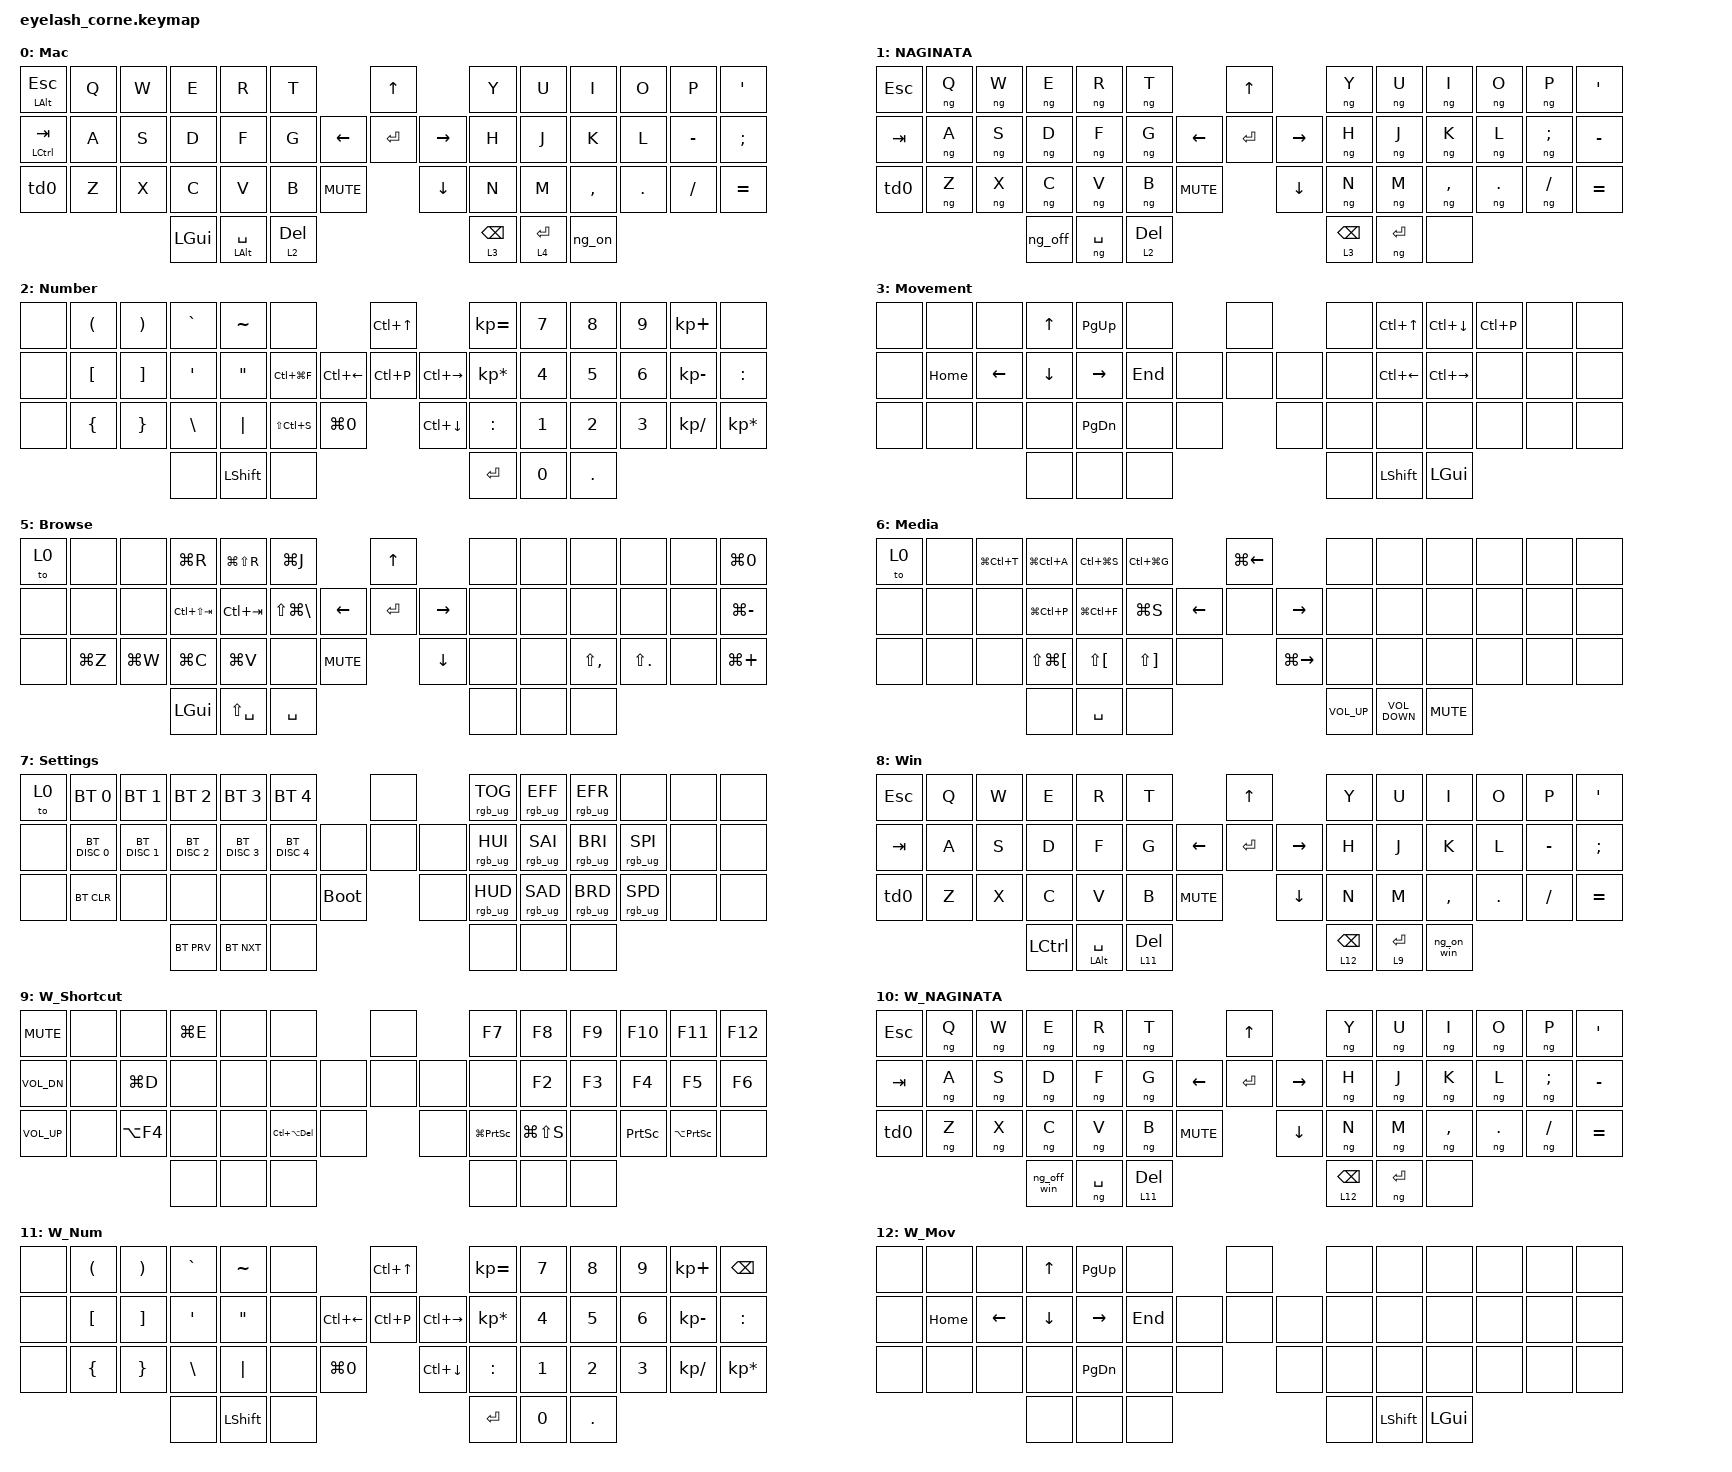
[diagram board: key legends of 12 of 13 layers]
#include <dt-bindings/zmk/mouse.h>
#include <input/processors.dtsi>
#include <behaviors/naginata.dtsi>
#include <behaviors.dtsi>
#include <dt-bindings/zmk/bt.h>
#include <dt-bindings/zmk/keys.h>
#include <dt-bindings/zmk/pointing.h>
#include <dt-bindings/zmk/rgb.h>

/*

   &mmv_input_listener {
       input-processors = <&zip_xy_scaler 2 1>;
   };

   &msc_input_listener {
       input-processors = <&zip_xy_scaler 2 1>;
   };

 */

#define ZMK_MOUSE_DEFAULT_MOVE_VAL 1200  // 600
#define ZMK_MOUSE_DEFAULT_SCRL_VAL 20    // 10

/ {
    behaviors {
        td0: td0 {
            compatible = "zmk,behavior-tap-dance";
            display-name = "Shift/Caps Lock Tap Dance";
            #binding-cells = <0>;
            bindings = <&kp LEFT_SHIFT>, <&kp CAPS>;

            label = "Shift";
        };

        mt_impl: mod-tap-by-hold-tap {
            compatible = "zmk,behavior-hold-tap";
            label = "MOD_TAP_BY_HOLD_TAP";
            #binding-cells = <2>;
            tapping-term-ms = <200>;
            quick-tap-ms = <0>;
            flavor = "hold-preferred";
            bindings = <&kp>, <&kp>;
        };

        lt_impl: layer-tap-by-hold-tap {
            compatible = "zmk,behavior-hold-tap";
            label = "LAYER_TAP_BY_HOLD_TAP";
            #binding-cells = <2>;
            tapping-term-ms = <200>;
            quick-tap-ms = <0>;
            flavor = "tap-preferred";
            bindings = <&mo>, <&kp>;
        };
    };

    rgb_encoder: rgb_encoder {
        compatible = "zmk,behavior-sensor-rotate";
        #sensor-binding-cells = <0>;
        bindings = <&rgb_ug RGB_BRI>, <&rgb_ug RGB_BRD>;
    };

    scroll_encoder: scroll_encoder {
        compatible = "zmk,behavior-sensor-rotate";
        #sensor-binding-cells = <0>;
        bindings = <&msc SCRL_DOWN>, <&msc SCRL_UP>;

        tap-ms = <30>;
    };

    macros {
        ng_on: ng_on {
            compatible = "zmk,behavior-macro";
            #binding-cells = <0>;
            bindings = <&macro_tap>, <&kp LANGUAGE_1 &kp INTERNATIONAL_4 &to 1>;
        };

        ng_off: ng_off {
            compatible = "zmk,behavior-macro";
            #binding-cells = <0>;
            bindings = <&macro_tap>, <&kp LANGUAGE_2 &kp INTERNATIONAL_5 &to 0>;
        };

        kakko: kakko {
            compatible = "zmk,behavior-macro";
            #binding-cells = <0>;
            bindings = <&macro_tap>, <&kp LEFT_PARENTHESIS &kp RPAR &kp LC(B)>;

            label = "KAKKO";
        };

        ng_kakko1: ng_kakko1 {
            compatible = "zmk,behavior-macro";
            #binding-cells = <0>;
            bindings =
                <&macro_tap>,
                <&kp LEFT_PARENTHESIS &kp RPAR &kp ENTER &kp LC(B)>;

            label = "NG_KAKKO1";
        };

        ng_kakko2: ng_kakko2 {
            compatible = "zmk,behavior-macro";
            #binding-cells = <0>;
            bindings = <&macro_tap>, <&kp LPAR &kp RPAR>;

            label = "NG_KAKKO2";
            wait-ms = <300>;
            tap-ms = <150>;
        };

        win_mode: win_mode {
            compatible = "zmk,behavior-macro";
            #binding-cells = <0>;
            bindings =
                <&macro_press>,
                <&to 8 &bt BT_SEL 1 &rgb_ug RGB_ON &rgb_ug RGB_COLOR_HSB(230,100,48) &rgb_ug RGB_EFF>;

            label = "WIN_MODE";
        };

        mac_mode: mac_mode {
            compatible = "zmk,behavior-macro";
            #binding-cells = <0>;
            bindings =
                <&macro_press>,
                <&to 0 &bt BT_SEL 0 &rgb_ug RGB_ON &rgb_ug RGB_COLOR_HSB(0,100,50) &rgb_ug RGB_EFR>;

            label = "MAC_MODE";
        };

        ng_off_win: ng_off_win {
            compatible = "zmk,behavior-macro";
            #binding-cells = <0>;
            bindings = <&macro_tap>, <&kp LANGUAGE_2 &kp INTERNATIONAL_5 &to 8>;

            label = "NG_OFF_WIN";
        };

        ng_on_win: ng_on_win {
            compatible = "zmk,behavior-macro";
            #binding-cells = <0>;
            bindings =
                <&macro_tap>,
                <&kp LANGUAGE_1 &kp INTERNATIONAL_4 &to 10>;

            label = "NG_ON_WIN";
        };
    };

    combos {
        compatible = "zmk,combos";

        Browse {
            bindings = <&to 5>;
            key-positions = <29 14>;
            layers = <0>;
        };

        Media {
            bindings = <&to 6>;
            key-positions = <15 30>;
            layers = <0>;
        };

        combo_ng_on {
            timeout-ms = <300>;
            key-positions = <22 23>;
            bindings = <&ng_on>;
            layers = <0>;
        };

        combo_ng_off {
            timeout-ms = <300>;
            key-positions = <17 18>;
            bindings = <&ng_off>;
            layers = <0 1>;
        };

        System {
            bindings = <&to 7>;
            key-positions = <40 26 11>;
            layers = <0>;
            timeout-ms = <300>;
        };

        ng_nakaguro {
            bindings = <&kp SLASH>;
            key-positions = <23 24 5>;
            layers = <1 10>;
            timeout-ms = <300>;
            require-prior-idle-ms = <0>;
        };

        ng_Kata {
            bindings = <&kp LC(K)>;
            key-positions = <24 38>;
            layers = <1>;
            timeout-ms = <300>;
        };

        Emo {
            bindings = <&kp LG(LC(SPACE))>;
            key-positions = <26 40>;
            layers = <1 0>;
            timeout-ms = <300>;
        };

        ng_Hira {
            bindings = <&kp LC(J)>;
            key-positions = <23 37>;
            timeout-ms = <300>;
            layers = <1>;
        };

        kakko {
            bindings = <&kakko>;
            key-positions = <23 24 17>;
            layers = <0 8>;
            timeout-ms = <300>;
        };

        ng_kakko1 {
            bindings = <&ng_kakko1>;
            key-positions = <17 23 24>;
            layers = <1 10>;
            timeout-ms = <300>;
        };

        ng_kakko2 {
            bindings = <&ng_kakko2>;
            key-positions = <24 15 25>;
            layers = <1 10>;
            timeout-ms = <300>;
            slow-release;
        };

        windowskey {
            bindings = <&kp LEFT_WIN>;
            key-positions = <42 43>;
            timeout-ms = <300>;
            layers = <8>;
        };

        win_mode {
            bindings = <&win_mode>;
            key-positions = <7 22 36>;
            layers = <0>;
            timeout-ms = <300>;
        };

        Mac_mode {
            bindings = <&mac_mode>;
            key-positions = <7 22 36>;
            layers = <8>;
            timeout-ms = <300>;
        };
    };

    keymap {
        compatible = "zmk,keymap";

        Mac {
            display-name = "Mac";
            bindings = <
&mt_impl LALT ESCAPE       &kp Q  &kp W  &kp E     &kp R                &kp T                                   &kp UP                &kp Y                 &kp U             &kp I      &kp O    &kp P      &kp SINGLE_QUOTE
&mt_impl LEFT_CONTROL TAB  &kp A  &kp S  &kp D     &kp F                &kp G                         &kp LEFT  &kp ENTER  &kp RIGHT  &kp H                 &kp J             &kp K      &kp L    &kp MINUS  &kp SEMI
&td0                       &kp Z  &kp X  &kp C     &kp V                &kp B           &kp K_MUTE              &kp DOWN              &kp N                 &kp M             &kp COMMA  &kp DOT  &kp FSLH   &kp EQUAL
                                         &kp LGUI  &mt_impl LALT SPACE  &lt_impl 2 DEL                                                &lt_impl 3 BACKSPACE  &lt_impl 4 ENTER  &ng_on
            >;

            sensor-bindings = <&inc_dec_kp C_VOLUME_UP C_VOLUME_DOWN>;
            label = "Mac";
        };

        naginata_layer {
            bindings = <
&kp ESCAPE  &ng Q  &ng W  &ng E    &ng R      &ng T                                   &kp UP                &ng Y                 &ng U      &ng I      &ng O    &ng P     &kp SINGLE_QUOTE
&kp TAB     &ng A  &ng S  &ng D    &ng F      &ng G                         &kp LEFT  &kp ENTER  &kp RIGHT  &ng H                 &ng J      &ng K      &ng L    &ng SEMI  &kp MINUS
&td0        &ng Z  &ng X  &ng C    &ng V      &ng B           &kp K_MUTE              &kp DOWN              &ng N                 &ng M      &ng COMMA  &ng DOT  &ng FSLH  &kp EQUAL
                          &ng_off  &ng SPACE  &lt_impl 2 DEL                                                &lt_impl 3 BACKSPACE  &ng ENTER  &none
            >;

            sensor-bindings = <&inc_dec_kp C_VOLUME_UP C_VOLUME_DOWN>;
            label = "NAGINATA";
        };

        Layer_2 {
            bindings = <
&none  &kp LPAR  &kp RPAR           &kp GRAVE         &kp TILDE          &none                                      &kp LC(UP_ARROW)                   &kp KP_EQUAL     &kp N7  &kp N8   &kp N9  &kp KP_PLUS      &none
&none  &kp LBKT  &kp RIGHT_BRACKET  &kp SINGLE_QUOTE  &kp DOUBLE_QUOTES  &kp LC(LG(F))                &kp LC(LEFT)  &kp LC(P)           &kp LC(RIGHT)  &kp KP_MULTIPLY  &kp N4  &kp N5   &kp N6  &kp KP_SUBTRACT  &kp COLON
&none  &kp LBRC  &kp RIGHT_BRACE    &kp BACKSLASH     &kp PIPE           &kp LS(LC(S))  &kp LG(N0)                  &kp LC(DOWN_ARROW)                 &kp COLON        &kp N1  &kp N2   &kp N3  &kp KP_DIVIDE    &kp KP_ASTERISK
                                    &none             &kp LSHFT          &none                                                                         &kp ENTER        &kp N0  &kp DOT
            >;

            label = "Number";
            sensor-bindings = <&inc_dec_kp LG(PLUS) LG(MINUS)>;
        };

        Layer_3 {
            bindings = <
&none  &none     &none     &kp UP_ARROW    &kp PAGE_UP    &none                    &none         &none  &kp LC(UP_ARROW)  &kp LC(DOWN_ARROW)  &kp LC(P)  &none  &none
&none  &kp HOME  &kp LEFT  &kp DOWN_ARROW  &kp RIGHT      &kp END           &none  &none  &none  &none  &kp LC(LEFT)      &kp LC(RIGHT)       &none      &none  &none
&none  &none     &none     &none           &kp PAGE_DOWN  &none    &none           &none         &none  &none             &none               &none      &none  &none
                           &none           &none          &none                                  &none  &kp LEFT_SHIFT    &kp LGUI
            >;

            sensor-bindings = <&scroll_encoder>;
            label = "Movement";
        };

        Layer_4 {
            bindings = <
&kp K_MUTE    &none  &none  &none  &none  &none                  &none         &kp F7                &kp F8                &kp F9          &kp F10                   &kp F11                   &kp F12
&kp C_VOL_DN  &none  &none  &none  &none  &none           &none  &none  &none  &kp F1                &kp F2                &kp F3          &kp F4                    &kp F5                    &kp F6
&kp C_VOL_UP  &none  &none  &none  &none  &none  &none           &none         &kp LG(LS(NUMBER_3))  &kp LS(LG(NUMBER_4))  &kp LS(LG(N5))  &kp LS(LC(LG(NUMBER_3)))  &kp LS(LC(LG(NUMBER_4)))  &none
                            &none  &none  &none                                &none                 &none                 &none
            >;

            sensor-bindings = <&scroll_encoder>;
            label = "Shortcuts";
        };

        layer_5 {
            bindings = <
&to 0  &none      &none      &kp LG(R)        &kp LG(LS(R))  &kp LG(J)                                      &kp UP_ARROW               &none  &none  &none          &none           &none  &kp LG(NUMBER_0)
&none  &none      &none      &kp LC(LS(TAB))  &kp LC(TAB)    &kp LS(LG(BACKSLASH))                &kp LEFT  &kp ENTER       &kp RIGHT  &none  &none  &none          &none           &none  &kp LG(MINUS)
&none  &kp LG(Z)  &kp LG(W)  &kp LG(C)        &kp LG(V)      &none                  &kp K_MUTE              &kp DOWN_ARROW             &none  &none  &kp LS(COMMA)  &kp LS(PERIOD)  &none  &kp LG(PLUS)
                             &kp LGUI         &kp LS(SPACE)  &kp SPACE                                                                 &none  &none  &none
            >;

            label = "Browse";
            sensor-bindings = <&inc_dec_kp C_VOLUME_UP C_VOLUME_DOWN>;
        };

        layer_6 {
            bindings = <
&to 0  &none  &kp LG(LC(T))  &kp LG(LC(A))             &kp LC(LG(S))         &kp LC(LG(G))                             &kp LG(LEFT)              &none            &none              &none       &none  &none  &none
&none  &none  &none          &kp LG(LC(P))             &kp LG(LC(F))         &kp LG(S)                       &kp LEFT  &none          &kp RIGHT  &none            &none              &none       &none  &none  &none
&none  &none  &none          &kp LS(LG(LEFT_BRACKET))  &kp LS(LEFT_BRACKET)  &kp LS(RIGHT_BRACKET)  &none              &kp LG(RIGHT)             &none            &none              &none       &none  &none  &none
                             &none                     &kp SPACE             &none                                                               &kp C_VOLUME_UP  &kp C_VOLUME_DOWN  &kp K_MUTE
            >;

            label = "Media";
            sensor-bindings = <&inc_dec_kp RIGHT LEFT>;
        };

        System {
            bindings = <
&to 0  &bt BT_SEL 0   &bt BT_SEL 1   &bt BT_SEL 2   &bt BT_SEL 3   &bt BT_SEL 4                         &none         &rgb_ug RGB_TOG  &rgb_ug RGB_EFF  &rgb_ug RGB_EFR  &none            &none  &none
&none  &bt BT_DISC 0  &bt BT_DISC 1  &bt BT_DISC 2  &bt BT_DISC 3  &bt BT_DISC 4                 &none  &none  &none  &rgb_ug RGB_HUI  &rgb_ug RGB_SAI  &rgb_ug RGB_BRI  &rgb_ug RGB_SPI  &none  &none
&none  &bt BT_CLR     &none          &none          &none          &none          &bootloader           &none         &rgb_ug RGB_HUD  &rgb_ug RGB_SAD  &rgb_ug RGB_BRD  &rgb_ug RGB_SPD  &none  &none
                                     &bt BT_PRV     &bt BT_NXT     &none                                              &none            &none            &none
            >;

            sensor-bindings = <&rgb_encoder>;
            label = "Settings";
        };

        Windows {
            display-name = "Win";
            bindings = <
&kp ESCAPE  &kp Q  &kp W  &kp E             &kp R           &kp T                                    &kp UP                &kp Y                  &kp U             &kp I       &kp O    &kp P      &kp SINGLE_QUOTE
&kp TAB     &kp A  &kp S  &kp D             &kp F           &kp G                          &kp LEFT  &kp ENTER  &kp RIGHT  &kp H                  &kp J             &kp K       &kp L    &kp MINUS  &kp SEMI
&td0        &kp Z  &kp X  &kp C             &kp V           &kp B            &kp K_MUTE              &kp DOWN              &kp N                  &kp M             &kp COMMA   &kp DOT  &kp FSLH   &kp EQUAL
                          &kp LEFT_CONTROL  &mt LALT SPACE  &lt_impl 11 DEL                                                &lt_impl 12 BACKSPACE  &lt_impl 9 ENTER  &ng_on_win
            >;

            sensor-bindings = <&inc_dec_kp C_VOLUME_UP C_VOLUME_DOWN>;
            label = "Win";
        };

        Win2 {
            label = "W_Shortcut";
            bindings = <
&kp K_MUTE    &none  &none       &kp LG(E)  &none  &none                            &none         &kp F7               &kp F8         &kp F9  &kp F10          &kp F11              &kp F12
&kp C_VOL_DN  &none  &kp LG(D)   &none      &none  &none                     &none  &none  &none  &none                &kp F2         &kp F3  &kp F4           &kp F5               &kp F6
&kp C_VOL_UP  &none  &kp LA(F4)  &none      &none  &kp LC(LA(DEL))  &none           &none         &kp LG(PRINTSCREEN)  &kp LG(LS(S))  &none   &kp PRINTSCREEN  &kp LA(PRINTSCREEN)  &none
                                 &none      &none  &none                                          &none                &none          &none
            >;

            sensor-bindings = <&scroll_encoder>;
        };

        layer_10 {
            label = "W_NAGINATA";
            bindings = <
&kp ESCAPE  &ng Q  &ng W  &ng E        &ng R      &ng T                                    &kp UP                &ng Y                  &ng U      &ng I      &ng O    &ng P     &kp SINGLE_QUOTE
&kp TAB     &ng A  &ng S  &ng D        &ng F      &ng G                          &kp LEFT  &kp ENTER  &kp RIGHT  &ng H                  &ng J      &ng K      &ng L    &ng SEMI  &kp MINUS
&td0        &ng Z  &ng X  &ng C        &ng V      &ng B            &kp K_MUTE              &kp DOWN              &ng N                  &ng M      &ng COMMA  &ng DOT  &ng FSLH  &kp EQUAL
                          &ng_off_win  &ng SPACE  &lt_impl 11 DEL                                                &lt_impl 12 BACKSPACE  &ng ENTER  &none
            >;

            sensor-bindings = <&inc_dec_kp C_VOLUME_UP C_VOLUME_DOWN>;
        };

        layer_11 {
            label = "W_Num";
            bindings = <
&none  &kp LPAR  &kp RPAR           &kp GRAVE         &kp TILDE          &none                              &kp LC(UP_ARROW)                   &kp KP_EQUAL     &kp N7  &kp N8   &kp N9  &kp KP_PLUS      &kp BACKSPACE
&none  &kp LBKT  &kp RIGHT_BRACKET  &kp SINGLE_QUOTE  &kp DOUBLE_QUOTES  &none                &kp LC(LEFT)  &kp LC(P)           &kp LC(RIGHT)  &kp KP_MULTIPLY  &kp N4  &kp N5   &kp N6  &kp KP_SUBTRACT  &kp COLON
&none  &kp LBRC  &kp RIGHT_BRACE    &kp BACKSLASH     &kp PIPE           &none  &kp LG(N0)                  &kp LC(DOWN_ARROW)                 &kp COLON        &kp N1  &kp N2   &kp N3  &kp KP_DIVIDE    &kp KP_ASTERISK
                                    &none             &kp LSHFT          &none                                                                 &kp ENTER        &kp N0  &kp DOT
            >;

            sensor-bindings = <&inc_dec_kp LG(PLUS) LG(MINUS)>;
        };

        layer_12 {
            label = "W_Mov";
            bindings = <
&none  &none     &none     &kp UP_ARROW    &kp PAGE_UP    &none                    &none         &none  &none           &none     &none  &none  &none
&none  &kp HOME  &kp LEFT  &kp DOWN_ARROW  &kp RIGHT      &kp END           &none  &none  &none  &none  &none           &none     &none  &none  &none
&none  &none     &none     &none           &kp PAGE_DOWN  &none    &none           &none         &none  &none           &none     &none  &none  &none
                           &none           &none          &none                                  &none  &kp LEFT_SHIFT  &kp LGUI
            >;

            sensor-bindings = <&scroll_encoder>;
        };
    };

    conditional_layers { compatible = "zmk,conditional-layers"; };
};
